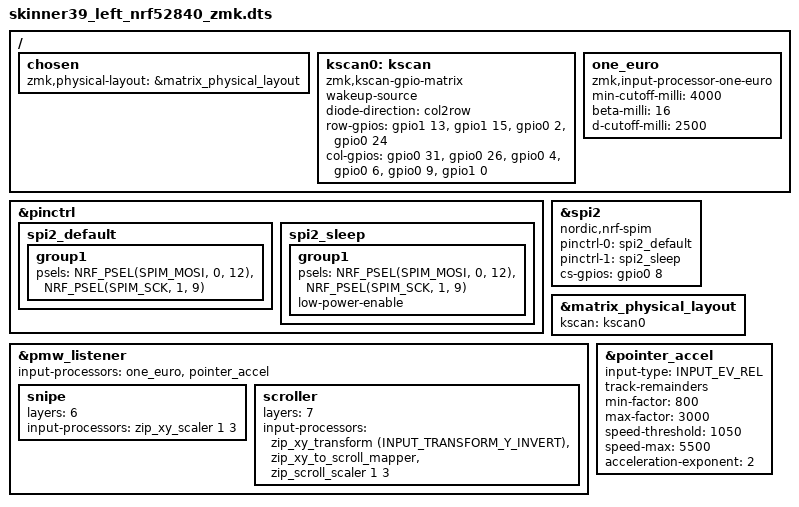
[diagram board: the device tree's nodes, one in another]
#include "skinner39.dtsi"
#include <dt-bindings/led/led.h>
#include <input/processors.dtsi>
#include <dt-bindings/zmk/input_transform.h>          /* INPUT_TRANSFORM_Y_INVERT (scroll Y-invert) */
#include <common/nordic/nrf52840_uf2_boot_mode.dtsi>  /* &bootloader: write Adafruit UF2 DFU magic so the bootloader STAYS in DFU */
#include <behaviors/input_gestures_accel.dtsi>        /* T1-A acceleration */


&pinctrl {
    spi2_default: spi2_default {
				group1 {
						psels = <NRF_PSEL(SPIM_MOSI, 0, 12)>,
						<NRF_PSEL(SPIM_SCK, 1, 9)>;
				};
		};
	
    spi2_sleep: spi2_sleep {
				group1 {
						psels = <NRF_PSEL(SPIM_MOSI, 0, 12)>,
						<NRF_PSEL(SPIM_SCK, 1, 9)>;
						low-power-enable;
				};
		};
};


lpm_view_spi: &spi2 {
    compatible = "nordic,nrf-spim";
    pinctrl-0 = <&spi2_default>;
    pinctrl-1 = <&spi2_sleep>;
    pinctrl-names = "default", "sleep";
    cs-gpios = <&gpio0 8 (GPIO_ACTIVE_HIGH | GPIO_PULL_DOWN) >;
};

nice_view_spi: &spi2 {
    compatible = "nordic,nrf-spim";
    pinctrl-0 = <&spi2_default>;
    pinctrl-1 = <&spi2_sleep>;
    pinctrl-names = "default", "sleep";
    cs-gpios = <&gpio0 8 (GPIO_ACTIVE_HIGH | GPIO_PULL_DOWN) >;
};



&matrix_physical_layout {
  	kscan = <&kscan0>;
};

/ {
	chosen {
		zmk,physical-layout = &matrix_physical_layout;
	};
    kscan0: kscan {
        compatible = "zmk,kscan-gpio-matrix";
        wakeup-source;

        diode-direction = "col2row";
        row-gpios
            = <&gpio1 13 (GPIO_ACTIVE_HIGH | GPIO_PULL_DOWN)>
            , <&gpio1 15 (GPIO_ACTIVE_HIGH | GPIO_PULL_DOWN)>
            , <&gpio0 2 (GPIO_ACTIVE_HIGH | GPIO_PULL_DOWN)>
            , <&gpio0 24 (GPIO_ACTIVE_HIGH | GPIO_PULL_DOWN)>
            ;

			col-gpios
							= <&gpio0 31 (GPIO_ACTIVE_HIGH | GPIO_PULL_DOWN)>
							, <&gpio0 26 (GPIO_ACTIVE_HIGH | GPIO_PULL_DOWN)>
							, <&gpio0 4 (GPIO_ACTIVE_HIGH | GPIO_PULL_DOWN)>
							, <&gpio0 6 (GPIO_ACTIVE_HIGH | GPIO_PULL_DOWN)>
							, <&gpio0 9 (GPIO_ACTIVE_HIGH | GPIO_PULL_DOWN)>
							, <&gpio1 0 (GPIO_ACTIVE_HIGH | GPIO_PULL_DOWN)>;
    };
};

&pmw_listener {
	status = "okay";

	/*
	 * SINGLE SOURCE OF TRUTH for trackball input-processors (T0).
	 * Topology: PMW3610 is on the RIGHT half -> BLE split -> these processors run
	 * HERE on the LEFT/central half. Layer indices (0-based):
	 *     6 = snipe  (reached via &mo 6 on macro_layer)
	 *     7 = scroll (reached via &lt 7 on the left thumb, default_layer pos 35)
	 * T1-A (acceleration) is LIVE in the base chain; tuned via &pointer_accel below.
	 * Tune per keysmith-design/06-trackball-T0-T1-implementation.md.
	 */

	/* Base chain (every layer): 1-Euro smoothing (T1-E) -> acceleration (T1-A).
	 * Order: smooth the deltas FIRST, then shape (accel). Snipe/scroll child
	 * overrides REPLACE this chain on their layers (no double-attenuation).
	 * T1-C (&zip_temp_mouse 4 300, motion->mouse_layer) RETIRED 2026-06-12: any ball
	 * jitter re-raised mouse_layer(4), turning the resting home row into mouse
	 * buttons (D = RCLK), and its excluded-positions meant pressing those keys never
	 * dismissed it — the "stuck on a right-click layer" complaint. Clicks live on
	 * the thumb &mkp keys; keymap layer 4 is now a retired placeholder. */
	input-processors = <&one_euro &pointer_accel>;

	/* SNIPE — layer 6: 1/3 precision. Stock zip_xy_scaler already tracks remainders. */
	snipe {
		layers = <6>;
		input-processors = <&zip_xy_scaler 1 3>;
	};

	/* SCROLL — layer 7: keep Y inverted (preference) -> map X/Y to wheel -> slow to 1/3.
	 * Order matters: transform (invert) BEFORE the scroll mapper; scale the WHEEL last.
	 * Tune the final divisor (1 3) for scroll speed; pairs with SMOOTH_SCROLLING. */
	scroller {
		layers = <7>;
		input-processors =
			<&zip_xy_transform (INPUT_TRANSFORM_Y_INVERT)>,
			<&zip_xy_to_scroll_mapper>,
			<&zip_scroll_scaler 1 3>;
	};
};

/* T1-A: acceleration parameters (velocity curve = auto-snipe at slow speed + reach at fast).
 * Patches the &pointer_accel node provided by <behaviors/input_gestures_accel.dtsi>.
 * TUNE on a FROZEN macOS curve:  defaults write -g com.apple.mouse.scaling -integer -1  (log out). */
&pointer_accel {
	input-type = <INPUT_EV_REL>;
	track-remainders;
	min-factor = <800>;           /* 0.8x at slow speed -> precision "just happens" */
	max-factor = <3000>;          /* 3.0x at fast speed -> reach (R3=3300 was too much; landed between R2 and R3) */
	speed-threshold = <1050>;     /* counts/s where factor = 1.0 (R2's gentler onset) */
	speed-max = <5500>;           /* counts/s where factor reaches max */
	acceleration-exponent = <2>;  /* quadratic */
};

/* T1-E: 1-Euro adaptive smoothing (custom module, DRAFT). Smooths the delta stream —
 * jitter kill at rest/slow speed, low lag when fast. Placed FIRST in the base chain.
 * Tune: min-cutoff (lower = smoother but more lag), beta (higher = less lag when fast).
 * Velocity estimate rides BLE burst cadence -> judge on USB. Needs CONFIG_FPU + 4096 stack. */
/ {
	one_euro: one_euro {
		compatible = "zmk,input-processor-one-euro";
		#input-processor-cells = <0>;
		min-cutoff-milli = <4000>;   /* 4.0 Hz floor cutoff (TUNED: between E1 and E2, toward E2) */
		beta-milli = <16>;           /* speed coeff (higher = sheds onset lag faster on fast moves) */
		d-cutoff-milli = <2500>;     /* 2.5 Hz derivative cutoff */
		/* ema-only; ema-alpha-milli = <400>;   // fallback: fixed EMA (simpler, more lag) */
	};
};
